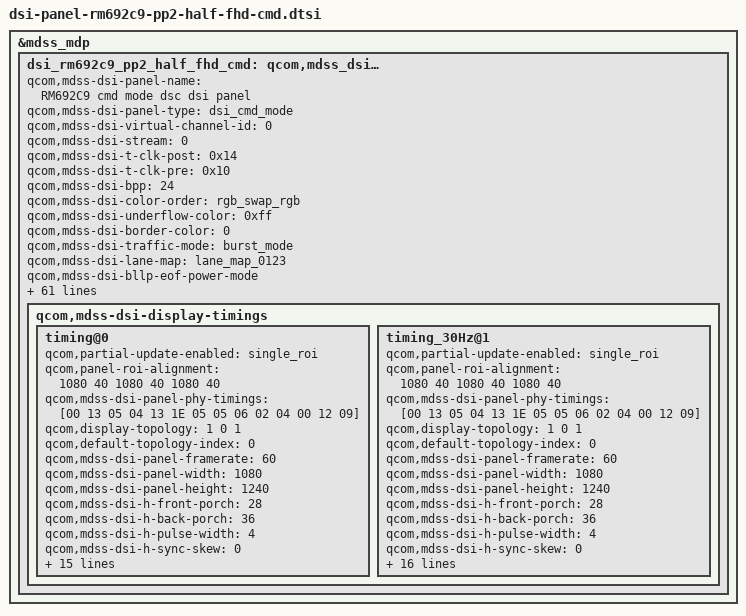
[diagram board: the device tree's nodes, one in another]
/* Copyright (c) 2014, Code Aurora Forum. All rights reserved.
 *
 * This program is free software; you can redistribute it and/or modify
 * it under the terms of the GNU General Public License version 2 and
 * only version 2 as published by the Free Software Foundation.
 *
 * This program is distributed in the hope that it will be useful,
 * but WITHOUT ANY WARRANTY; without even the implied warranty of
 * MERCHANTABILITY or FITNESS FOR A PARTICULAR PURPOSE.  See the
 * GNU General Public License for more details.
 */

&mdss_mdp {
    dsi_rm692c9_pp2_half_fhd_cmd: qcom,mdss_dsi_rm692c9_pp2_half_fhd_cmd {
		qcom,mdss-dsi-panel-name = "RM692C9 cmd mode dsc dsi panel";
		qcom,mdss-dsi-panel-type = "dsi_cmd_mode";
		qcom,mdss-dsi-virtual-channel-id = <0>;
		qcom,mdss-dsi-stream = <0>;
		qcom,mdss-dsi-t-clk-post = <0x14>;
		qcom,mdss-dsi-t-clk-pre = <0x10>;
		qcom,mdss-dsi-bpp = <24>;
		qcom,mdss-dsi-color-order = "rgb_swap_rgb";
		qcom,mdss-dsi-underflow-color = <0xff>;
		qcom,mdss-dsi-border-color = <0>;
		qcom,mdss-dsi-traffic-mode = "burst_mode";
		qcom,mdss-dsi-lane-map = "lane_map_0123";
		qcom,mdss-dsi-bllp-eof-power-mode;
		qcom,mdss-dsi-bllp-power-mode;
		qcom,mdss-dsi-lane-0-state;
		qcom,mdss-dsi-lane-1-state;
		qcom,mdss-dsi-lane-2-state;
		qcom,mdss-dsi-lane-3-state;
		qcom,mdss-dsi-reset-sequence = <1 10>, <0 2>, <1 10>;
		qcom,mdss-dsi-dma-trigger = "trigger_sw";
		qcom,mdss-dsi-mdp-trigger = "none";
		qcom,mdss-dsi-te-pin-select = <1>;
		qcom,panel-te-source = <1>;
		qcom,mdss-dsi-wr-mem-start = <0x2c>;
		qcom,mdss-dsi-wr-mem-continue = <0x3c>;
		qcom,mdss-dsi-te-dcs-command = <1>;
//		qcom,mdss-dsi-te-check-enable;
//		qcom,mdss-dsi-te-using-te-pin;
		qcom,mdss-dsi-lp11-init;
		qcom,mdss-dsi-tx-eot-append;
		qcom,dsi-sec-ctrl-num = <1>;
		qcom,dsi-sec-phy-num = <1>;
		/* qcom,dsi-select-sec-clocks = "src_byte_clk1", "src_pixel_clk1"; */
		qcom,dsi-select-sec-clocks = "mux_byte_clk1", "mux_pixel_clk1";
		qcom,ulps-enabled;
		//qcom,null-insertion-enabled;

		qcom,mdss-dsi-panel-hdr-enabled;
		qcom,mdss-dsi-panel-hdr-color-primaries = <14880 15935 32435 16555 14945 30910 7790 3415>;
		qcom,mdss-dsi-panel-peak-brightness = <5000000>;		/* max. 500nits */
		qcom,mdss-dsi-panel-blackness-level = <6134>;

		qcom,mdss-pan-physical-width-dimension = <69>;
		qcom,mdss-pan-physical-height-dimension = <80>;

		/* Brightness Map List */
		lge,blmap = <
			0
			//0%[10]
			9 9 9 9 9 9 9 9 9 9 10 10 10
			//1%[0] 2%[2] 3%[5] 4%[7] 5%[10] 6%[12] 7%[15] 8%[17] 9%[20] 10%[22]
			10 10 11 11 11 11 11 12 12 12 13 13 14 14 15 16 16 17 17 18 19 21 23 24
			//11%[0] 12%[3] 13%[5] 14%[8] 15%[10] 16%[13] 17%[15] 18%[18] 19%[20] 20%[22]
			26 27 28 29 31 33 34 35 37 39 41 43 45 47 49 51 53 55 57 59 62 65 68 69 71
			//21%[0] 22%[2] 23%[5] 24%[7] 25%[10] 26%[12] 27%[15] 28%[17] 29%[20] 30%[22]
			73 76 80 82 85 88 92 96 98 101 104 107 111 114 117 121 126 131 134 137 140 145 151 156
			//31%[0] 32%[3] 33%[5] 34%[8] 35%[10] 36%[13] 37%[15] 38%[18] 39%[20] 40%[22]
			162 165 169 173 178 184 188 192 197 203 210 214 218 222 228 235 239 243 248 254 260 268 277 282 288
			//41%[0] 42%[2] 43%[5] 44%[7] 45%[10] 46%[12] 47%[15] 48%[17] 49%[20] 50%[22]
			294 302 311 316 321 326 335 345 350 355 361 370 379 384 390 396 405 415 421 427 434 443 452 462
			//51%[0] 52%[3] 53%[5] 54%[8] 55%[10] 56%[13] 57%[15] 58%[18] 59%[20] 60%[22]
			472 478 485 492 503 514 520 527 534 545 556 563 570 578 588 599 606 614 622 634 646 657 669 677 686
			//61%[0] 62%[2] 63%[5] 64%[7] 65%[10] 66%[12] 67%[15] 68%[17] 69%[20] 70%[22]
			695 707 719 727 736 745 756 768 777 786 796 808 821 830 839 848 862 876 886 896 906 919 933 947
			//71%[0] 72%[3] 73%[5] 74%[8] 75%[10] 76%[13] 77%[15] 78%[18] 79%[20] 80%[22]
			961 971 981 991 1006 1021 1031 1041 1051 1065 1080 1091 1102 1114 1129 1144 1155 1167 1179 1198 1218 1233 1248 1259 1271
			//81%[0] 82%[2] 83%[5] 84%[7] 85%[10] 86%[12] 87%[15] 88%[17] 89%[20] 90%[22]
			1283 1300 1317 1330 1343 1356 1376 1396 1410 1424 1438 1457 1477 1490 1503 1517 1538 1560 1574 1588 1602 1622 1642 1661
			//91%[0] 92%[3] 93%[5] 94%[8] 95%[10] 96%[13] 97%[15] 98%[18] 99%[20] 100%[22]
			1681 1693 1705 1718 1738 1759 1772 1786 1800 1821 1843 1856 1870 1884 1904 1925 1940 1955 1971 1992 2014 2070 2126
			2127 2127 2127 2127 2128 2129 2130 2131 2133 2134 2137 2139 2142 2144 2148 2151 2155 2159 2163 2168 2173 2178 2184 2189 2196
			2202 2209 2216 2223 2231 2239 2248 2257 2266 2275 2285 2295 2306 2316 2328 2339 2351 2363 2376 2389 2402 2416 2430 2444 2459
			2474 2489 2505 2521 2538 2555 2572 2590 2608 2626 2645 2664 2684 2704 2724 2745 2766 2788 2810 2832 2855 2878 2901 2925 2949
			2974 2999 3024 3050 3077 3103 3130 3158 3186 3214 3243 3272 3301 3331 3361 3392 3423 3455 3487 3519 3552 3585 3619 3653 3687
			3722 3758 3793 3829 3866 3903 3940 3978 4017 4055
		>;
		lge,blmap-ve = <
			0
			//0%[10]
			9 9 9 9 9 9 9 9 9 9 10 10 10
			//1%[0] 2%[2] 3%[5] 4%[7] 5%[10] 6%[12] 7%[15] 8%[17] 9%[20] 10%[22]
			10 10 11 11 11 11 11 12 12 12 13 13 14 14 15 16 16 17 17 18 19 21 23 24
			//11%[0] 12%[3] 13%[5] 14%[8] 15%[10] 16%[13] 17%[15] 18%[18] 19%[20] 20%[22]
			26 27 28 29 31 33 34 35 37 39 41 43 45 47 49 51 53 55 57 59 62 65 68 69 71
			//21%[0] 22%[2] 23%[5] 24%[7] 25%[10] 26%[12] 27%[15] 28%[17] 29%[20] 30%[22]
			73 76 80 82 85 88 92 96 98 101 104 107 111 114 117 121 126 131 134 137 140 145 151 156
			//31%[0] 32%[3] 33%[5] 34%[8] 35%[10] 36%[13] 37%[15] 38%[18] 39%[20] 40%[22]
			162 165 169 173 178 184 188 192 197 203 210 214 218 222 228 235 239 243 248 254 260 268 277 282 288
			//41%[0] 42%[2] 43%[5] 44%[7] 45%[10] 46%[12] 47%[15] 48%[17] 49%[20] 50%[22]
			294 302 311 316 321 326 335 345 350 355 361 370 379 384 390 396 405 415 421 427 434 443 452 462
			//51%[0] 52%[3] 53%[5] 54%[8] 55%[10] 56%[13] 57%[15] 58%[18] 59%[20] 60%[22]
			472 478 485 492 503 514 520 527 534 545 556 563 570 578 588 599 606 614 622 634 646 657 669 677 686
			//61%[0] 62%[2] 63%[5] 64%[7] 65%[10] 66%[12] 67%[15] 68%[17] 69%[20] 70%[22]
			695 707 719 727 736 745 756 768 777 786 796 808 821 830 839 848 862 876 886 896 906 919 933 947
			//71%[0] 72%[3] 73%[5] 74%[8] 75%[10] 76%[13] 77%[15] 78%[18] 79%[20] 80%[22]
			961 971 981 991 1006 1021 1031 1041 1051 1065 1080 1091 1102 1114 1129 1144 1155 1167 1179 1198 1218 1233 1248 1259 1271
			//81%[0] 82%[2] 83%[5] 84%[7] 85%[10] 86%[12] 87%[15] 88%[17] 89%[20] 90%[22]
			1283 1300 1317 1330 1343 1356 1376 1396 1410 1424 1438 1457 1477 1490 1503 1517 1538 1560 1574 1588 1602 1622 1642 1661
			//91%[0] 92%[3] 93%[5] 94%[8] 95%[10] 96%[13] 97%[15] 98%[18] 99%[20] 100%[22]
			1681 1693 1705 1718 1738 1759 1772 1786 1800 1821 1843 1856 1870 1884 1904 1925 1940 1955 1971 1992 2014 2070 2126
			2127 2127 2127 2127 2128 2129 2130 2131 2133 2134 2137 2139 2142 2144 2148 2151 2155 2159 2163 2168 2173 2178 2184 2189 2196
			2202 2209 2216 2223 2231 2239 2248 2257 2266 2275 2285 2295 2306 2316 2328 2339 2351 2363 2376 2389 2402 2416 2430 2444 2459
			2474 2489 2505 2521 2538 2555 2572 2590 2608 2626 2645 2664 2684 2704 2724 2745 2766 2788 2810 2832 2855 2878 2901 2925 2949
			2974 2999 3024 3050 3077 3103 3130 3158 3186 3214 3243 3272 3301 3331 3361 3392 3423 3455 3487 3519 3552 3585 3619 3653 3687
			3722 3758 3793 3829 3866 3903 3940 3978 4017 4055
		>;
		lge,blmap-hdr = <
			0
			//0%[10]
			9 9 9 9 9 9 9 9 9 9 10 10 10
			//1%[0] 2%[2] 3%[5] 4%[7] 5%[10] 6%[12] 7%[15] 8%[17] 9%[20] 10%[22]
			10 10 11 11 11 11 11 12 12 12 13 13 14 14 15 16 16 17 17 18 19 21 23 24
			//11%[0] 12%[3] 13%[5] 14%[8] 15%[10] 16%[13] 17%[15] 18%[18] 19%[20] 20%[22]
			26 27 28 29 31 33 34 35 37 39 41 43 45 47 49 51 53 55 57 59 62 65 68 69 71
			//21%[0] 22%[2] 23%[5] 24%[7] 25%[10] 26%[12] 27%[15] 28%[17] 29%[20] 30%[22]
			73 76 80 82 85 88 92 96 98 101 104 107 111 114 117 121 126 131 134 137 140 145 151 156
			//31%[0] 32%[3] 33%[5] 34%[8] 35%[10] 36%[13] 37%[15] 38%[18] 39%[20] 40%[22]
			162 165 169 173 178 184 188 192 197 203 210 214 218 222 228 235 239 243 248 254 260 268 277 282 288
			//41%[0] 42%[2] 43%[5] 44%[7] 45%[10] 46%[12] 47%[15] 48%[17] 49%[20] 50%[22]
			294 302 311 316 321 326 335 345 350 355 361 370 379 384 390 396 405 415 421 427 434 443 452 462
			//51%[0] 52%[3] 53%[5] 54%[8] 55%[10] 56%[13] 57%[15] 58%[18] 59%[20] 60%[22]
			472 478 485 492 503 514 520 527 534 545 556 563 570 578 588 599 606 614 622 634 646 657 669 677 686
			//61%[0] 62%[2] 63%[5] 64%[7] 65%[10] 66%[12] 67%[15] 68%[17] 69%[20] 70%[22]
			695 707 719 727 736 745 756 768 777 786 796 808 821 830 839 848 862 876 886 896 906 919 933 947
			//71%[0] 72%[3] 73%[5] 74%[8] 75%[10] 76%[13] 77%[15] 78%[18] 79%[20] 80%[22]
			961 971 981 991 1006 1021 1031 1041 1051 1065 1080 1091 1102 1114 1129 1144 1155 1167 1179 1198 1218 1233 1248 1259 1271
			//81%[0] 82%[2] 83%[5] 84%[7] 85%[10] 86%[12] 87%[15] 88%[17] 89%[20] 90%[22]
			1283 1300 1317 1330 1343 1356 1376 1396 1410 1424 1438 1457 1477 1490 1503 1517 1538 1560 1574 1588 1602 1622 1642 1661
			//91%[0] 92%[3] 93%[5] 94%[8] 95%[10] 96%[13] 97%[15] 98%[18] 99%[20] 100%[22]
			1681 1693 1705 1718 1738 1759 1772 1786 1800 1821 1843 1856 1870 1884 1904 1925 1940 1955 1971 1992 2014 2070 2126
			2127 2127 2127 2127 2128 2129 2130 2131 2133 2134 2137 2139 2142 2144 2148 2151 2155 2159 2163 2168 2173 2178 2184 2189 2196
			2202 2209 2216 2223 2231 2239 2248 2257 2266 2275 2285 2295 2306 2316 2328 2339 2351 2363 2376 2389 2402 2416 2430 2444 2459
			2474 2489 2505 2521 2538 2555 2572 2590 2608 2626 2645 2664 2684 2704 2724 2745 2766 2788 2810 2832 2855 2878 2901 2925 2949
			2974 2999 3024 3050 3077 3103 3130 3158 3186 3214 3243 3272 3301 3331 3361 3392 3423 3455 3487 3519 3552 3585 3619 3653 3687
			3722 3758 3793 3829 3866 3903 3940 3978 4017 4055
		>;

		lge,use-color-manager;
		lge,use-color-manager-oled;

		lge,mdss-dsi-disp-ctrl-command-1 = [
			15 01 00 00 00 00 02 FE 00
			15 01 00 00 00 00 02 5C 00
			15 01 00 00 00 00 02 FE 80
			15 01 00 00 00 00 02 00 4F
			15 01 00 00 00 00 02 05 00
			15 00 00 00 00 00 02 FE 12
			15 00 00 00 00 00 02 84 00
			15 01 00 00 00 00 02 FE 00
		];
		lge,mdss-dsi-disp-ctrl-command-1-state = "dsi_lp_mode";

		lge,color-mode-cmds-dummy = [
			15 00 00 00 00 00 02 FE 00
			15 00 00 00 00 00 02 5A 0B
			15 00 00 00 00 00 02 5C 00
			15 00 00 00 00 00 02 FE 80
			15 00 00 00 00 00 02 00 4F
			15 00 00 00 00 00 02 08 DF
			15 00 00 00 00 00 02 09 EE
			15 00 00 00 00 00 02 0A ED
			15 00 00 00 00 00 02 0B FC
			15 00 00 00 00 00 02 0C F0
			15 00 00 00 00 00 02 0D FB
			15 00 00 00 00 00 02 0E 00
			15 00 00 00 00 00 02 0F 01
			15 00 00 00 00 00 02 14 3F
			15 00 00 00 00 00 02 15 B3
			15 00 00 00 00 00 02 16 74
			15 00 00 00 00 00 02 17 FF
			15 00 00 00 00 00 02 18 AD
			15 00 00 00 00 00 02 19 3F
			15 00 00 00 00 00 02 1A C9
			15 00 00 00 00 00 02 1B 07
			15 00 00 00 00 00 02 FE 10
			15 00 00 00 00 00 02 00 9C
			15 00 00 00 00 00 02 01 57
			15 00 00 00 00 00 02 02 05
			15 00 00 00 00 00 02 03 14
			15 00 00 00 00 00 02 04 10
			15 00 00 00 00 00 02 05 01
			15 00 00 00 00 00 02 06 6C
			15 00 00 00 00 00 02 07 A7
			15 00 00 00 00 00 02 08 02
			15 00 00 00 00 00 02 09 06
			15 00 00 00 00 00 02 0A 00
			15 00 00 00 00 00 02 0B 00
			15 00 00 00 00 00 02 0C 8D
			15 00 00 00 00 00 02 0D 07
			15 00 00 00 00 00 02 FE 12
			15 00 00 00 00 00 02 84 00
			15 00 00 00 00 00 02 83 10
			15 01 00 00 00 00 02 FE 00
		];
		lge,color-mode-cmds-dummy-state = "dsi_lp_mode";

		lge,use-color-manager-lut;
		lge,cm-lut-screen-mode-set-name = "nat", "viv", "cin";
		lge,cm-lut-screen-mode-set-cnt = <40>;
		lge,cm-lut-screen-mode-set = [
			00 0B 00 80 4F DF EE ED FC F0 FB 00 01 3F B3 74 FF AD 3F C9 07 10 9C 57 05 14 10 01 6C A7 02 06 00 00 8D 07 12 00 10 00
			00 0B 00 80 4F 80 33 0E 23 32 62 EF 0F 14 2C 5F F7 FF 06 97 0B 10 3C 57 05 14 10 01 5C A7 02 06 00 00 EF 07 12 00 10 00
			00 0B 00 80 4F 00 00 EF FF DE EE 0F 00 3F EF 14 FF CD 35 CD 03 10 AF 57 05 14 10 01 A0 A7 02 06 00 00 10 07 12 00 10 00
		];

		lge,cm-lut-hue-cnt = <8>;
		lge,cm-lut-hue = [
			D8 49 B9 71 39 93 00 00
			84 06 97 40 F3 61 00 02
			3F B3 74 FF AD 3F C9 07
			FB 71 51 BE 57 FC CB 0F
			C6 2E 3D 7D 11 C9 DF 0F
		];

		lge,cm-lut-saturation-cnt = <13>;
		lge,cm-lut-saturation = [
			00 0B 00 80 4F 99 AA A9 98 9A 95 00 00
			00 0B 00 80 4F BC CC CB CA CD C8 00 00
			00 0B 00 80 4F DF EE ED FC F0 FB 00 01
			00 0B 00 80 4F F2 00 0F 2E 23 2E AD 0B
			00 0B 00 80 4F 15 22 21 50 56 51 FF 0F
		];

		lge,cm-lut-sharpness-cnt = <1>;
		lge,cm-lut-sharpness = [08 12 1C 26 30];

		lge,cm-lut-rgb-cnt = <14>;
		lge,cm-lut-rgb = [
			1C 57 05 14 10 01 C0 A7 02 06 00 00 23 07
			7C 57 05 14 10 01 C0 A7 02 06 00 00 77 07
			9C 57 05 14 10 01 6C A7 02 06 00 00 8D 07
			9C 57 05 14 10 01 2C A7 02 06 00 00 92 07
			9C 57 05 14 10 01 DC A6 02 06 00 00 98 07
		];

		/* Video Enahnacement */
		lge,mdss-dsi-ve-on-command = [
			15 00 00 00 00 00 02 FE 80
			15 00 00 00 00 00 02 00 4F
			15 00 00 00 00 00 02 08 F2
			15 00 00 00 00 00 02 09 00
			15 00 00 00 00 00 02 0A 0F
			15 00 00 00 00 00 02 0B 2E
			15 00 00 00 00 00 02 0C 23
			15 00 00 00 00 00 02 0D 2E
			15 00 00 00 00 00 02 0E AD
			15 00 00 00 00 00 02 0F 0B
			15 01 00 00 00 00 02 FE 00
		];
		lge,mdss-dsi-ve-on-command-state = "dsi_lp_mode";

		qcom,mdss-dsi-display-timings {
			timing@0{
				qcom,partial-update-enabled = "single_roi";
				qcom,panel-roi-alignment = <1080 40 1080 40 1080 40>;
				qcom,mdss-dsi-panel-phy-timings = [00 13 05 04 13 1E 05 05 06 02 04 00 12 09];
				//qcom,mdss-dsi-panel-clockrate = <435355200>;
				qcom,display-topology = <1 0 1>;
				qcom,default-topology-index = <0>;
				qcom,mdss-dsi-panel-framerate = <60>;
				qcom,mdss-dsi-panel-width = <1080>;
				qcom,mdss-dsi-panel-height = <1240>;
				qcom,mdss-dsi-h-front-porch = <28>;
				qcom,mdss-dsi-h-back-porch = <36>;
				qcom,mdss-dsi-h-pulse-width = <4>;
				qcom,mdss-dsi-h-sync-skew = <0>;
				qcom,mdss-dsi-v-back-porch = <8>;
				qcom,mdss-dsi-v-front-porch = <16>;
				qcom,mdss-dsi-v-pulse-width = <4>;
				qcom,mdss-dsi-h-left-border = <0>;
				qcom,mdss-dsi-h-right-border = <0>;
				qcom,mdss-dsi-v-top-border = <0>;
				qcom,mdss-dsi-v-bottom-border = <0>;
				qcom,mdss-dsi-h-sync-pulse = <0>;
				//qcom,mdss-mdp-transfer-time-us = <15000>;

				qcom,mdss-dsi-on-command = [
					15 00 00 00 00 00 02 FE 00
					15 00 00 00 00 00 02 5A 0B
					15 00 00 00 00 00 02 5C 00
					15 01 00 00 00 00 02 FE 00
					15 00 00 00 00 00 02 FE 80
					15 00 00 00 00 00 02 00 4F
					15 00 00 00 00 00 02 08 DF
					15 00 00 00 00 00 02 09 EE
					15 00 00 00 00 00 02 0A ED
					15 00 00 00 00 00 02 0B FC
					15 00 00 00 00 00 02 0C F0
					15 00 00 00 00 00 02 0D FB
					15 00 00 00 00 00 02 0E 00
					15 00 00 00 00 00 02 0F 01
					15 00 00 00 00 00 02 14 3F
					15 00 00 00 00 00 02 15 B3
					15 00 00 00 00 00 02 16 74
					15 00 00 00 00 00 02 17 FF
					15 00 00 00 00 00 02 18 AD
					15 00 00 00 00 00 02 19 3F
					15 00 00 00 00 00 02 1A C9
					15 00 00 00 00 00 02 1B 07
					15 01 00 00 00 00 02 FE 00
					15 00 00 00 00 00 02 FE 10
					15 00 00 00 00 00 02 00 9C
					15 00 00 00 00 00 02 01 57
					15 00 00 00 00 00 02 02 05
					15 00 00 00 00 00 02 03 14
					15 00 00 00 00 00 02 04 10
					15 00 00 00 00 00 02 05 01
					15 00 00 00 00 00 02 06 6C
					15 00 00 00 00 00 02 07 A7
					15 00 00 00 00 00 02 08 02
					15 00 00 00 00 00 02 09 06
					15 00 00 00 00 00 02 0A 00
					15 00 00 00 00 00 02 0B 00
					15 00 00 00 00 00 02 0C 8D
					15 00 00 00 00 00 02 0D 07
					15 01 00 00 00 00 02 FE 00
					15 00 00 00 00 00 02 FE 10
					15 00 00 00 00 00 02 0E 00
					15 00 00 00 00 00 02 0F 00
					15 00 00 00 00 00 02 10 00
					15 00 00 00 00 00 02 11 01
					15 00 00 00 00 00 02 12 00
					15 00 00 00 00 00 02 13 07
					15 00 00 00 00 00 02 14 12
					15 00 00 00 00 00 02 15 00
					15 00 00 00 00 00 02 16 19
					15 00 00 00 00 00 02 17 23
					15 00 00 00 00 00 02 18 00
					15 00 00 00 00 00 02 19 2D
					15 00 00 00 00 00 02 1A 33
					15 00 00 00 00 00 02 1B 00
					15 00 00 00 00 00 02 1C 3A
					15 00 00 00 00 00 02 1D 58
					15 00 00 00 00 00 02 1E 00
					15 00 00 00 00 00 02 1F 7D
					15 00 00 00 00 00 02 20 93
					15 00 00 00 00 00 02 21 00
					15 00 00 00 00 00 02 22 AA
					15 00 00 00 00 00 02 23 DF
					15 00 00 00 00 00 02 24 10
					15 00 00 00 00 00 02 25 1D
					15 00 00 00 00 00 02 26 62
					15 00 00 00 00 00 02 27 11
					15 00 00 00 00 00 02 28 B1
					15 00 00 00 00 00 02 29 08
					15 00 00 00 00 00 02 2A 22
					15 00 00 00 00 00 02 2B 69
					15 00 00 00 00 00 02 2D D3
					15 00 00 00 00 00 02 2F 32
					15 00 00 00 00 00 02 30 47
					15 00 00 00 00 00 02 31 C5
					15 00 00 00 00 00 02 32 43
					15 00 00 00 00 00 02 33 4C
					15 00 00 00 00 00 02 34 DE
					15 00 00 00 00 00 02 35 54
					15 00 00 00 00 00 02 36 7A
					15 00 00 00 00 00 02 37 20
					15 00 00 00 00 00 02 38 66
					15 00 00 00 00 00 02 39 D1
					15 00 00 00 00 00 02 3A 8D
					15 00 00 00 00 00 02 3B 87
					15 00 00 00 00 00 02 3D 54
					15 00 00 00 00 00 02 3F 26
					15 00 00 00 00 00 02 40 A9
					15 00 00 00 00 00 02 41 03
					15 00 00 00 00 00 02 42 EB
					15 00 00 00 00 00 02 43 BA
					15 00 00 00 00 00 02 44 DF
					15 00 00 00 00 00 02 45 DF
					15 00 00 00 00 00 02 46 DC
					15 00 00 00 00 00 02 47 EA
					15 00 00 00 00 00 02 48 01
					15 00 00 00 00 00 02 49 FF
					15 00 00 00 00 00 02 4A 91
					15 00 00 00 00 00 02 4B DA
					15 00 00 00 00 00 02 4C FF
					15 00 00 00 00 00 02 4D FF
					15 00 00 00 00 00 02 4E 00
					15 00 00 00 00 00 02 4F 00
					15 00 00 00 00 00 02 50 00
					15 00 00 00 00 00 02 51 02
					15 00 00 00 00 00 02 52 00
					15 00 00 00 00 00 02 53 08
					15 00 00 00 00 00 02 54 13
					15 00 00 00 00 00 02 55 00
					15 00 00 00 00 00 02 56 1B
					15 00 00 00 00 00 02 58 25
					15 00 00 00 00 00 02 59 00
					15 00 00 00 00 00 02 5A 30
					15 00 00 00 00 00 02 5B 36
					15 00 00 00 00 00 02 5C 00
					15 00 00 00 00 00 02 5D 3D
					15 00 00 00 00 00 02 5E 5C
					15 00 00 00 00 00 02 5F 00
					15 00 00 00 00 00 02 60 83
					15 00 00 00 00 00 02 61 99
					15 00 00 00 00 00 02 62 00
					15 00 00 00 00 00 02 63 B2
					15 00 00 00 00 00 02 64 E8
					15 00 00 00 00 00 02 65 10
					15 00 00 00 00 00 02 66 27
					15 00 00 00 00 00 02 67 6E
					15 00 00 00 00 00 02 68 11
					15 00 00 00 00 00 02 69 BE
					15 00 00 00 00 00 02 6A 17
					15 00 00 00 00 00 02 6B 22
					15 00 00 00 00 00 02 6C 79
					15 00 00 00 00 00 02 6D E4
					15 00 00 00 00 00 02 6E 32
					15 00 00 00 00 00 02 6F 59
					15 00 00 00 00 00 02 70 D7
					15 00 00 00 00 00 02 71 43
					15 00 00 00 00 00 02 72 5F
					15 00 00 00 00 00 02 73 F1
					15 00 00 00 00 00 02 74 54
					15 00 00 00 00 00 02 75 8E
					15 00 00 00 00 00 02 76 34
					15 00 00 00 00 00 02 77 66
					15 00 00 00 00 00 02 78 E5
					15 00 00 00 00 00 02 79 A0
					15 00 00 00 00 00 02 7A 87
					15 00 00 00 00 00 02 7B 66
					15 00 00 00 00 00 02 7C 37
					15 00 00 00 00 00 02 7D A9
					15 00 00 00 00 00 02 7E 13
					15 00 00 00 00 00 02 7F F9
					15 00 00 00 00 00 02 80 BA
					15 00 00 00 00 00 02 81 EB
					15 00 00 00 00 00 02 82 E8
					15 00 00 00 00 00 02 83 DC
					15 00 00 00 00 00 02 84 F1
					15 00 00 00 00 00 02 85 04
					15 00 00 00 00 00 02 86 FF
					15 00 00 00 00 00 02 87 92
					15 00 00 00 00 00 02 88 DB
					15 00 00 00 00 00 02 89 FF
					15 00 00 00 00 00 02 8A FF
					15 00 00 00 00 00 02 8B 00
					15 00 00 00 00 00 02 8C 00
					15 00 00 00 00 00 02 8D 00
					15 00 00 00 00 00 02 8E 02
					15 00 00 00 00 00 02 8F 00
					15 00 00 00 00 00 02 90 08
					15 00 00 00 00 00 02 91 15
					15 00 00 00 00 00 02 92 00
					15 00 00 00 00 00 02 93 1D
					15 00 00 00 00 00 02 94 27
					15 00 00 00 00 00 02 95 00
					15 00 00 00 00 00 02 96 33
					15 00 00 00 00 00 02 97 3A
					15 00 00 00 00 00 02 98 00
					15 00 00 00 00 00 02 99 41
					15 00 00 00 00 00 02 9A 61
					15 00 00 00 00 00 02 9B 00
					15 00 00 00 00 00 02 9C 89
					15 00 00 00 00 00 02 9D A0
					15 00 00 00 00 00 02 9E 00
					15 00 00 00 00 00 02 9F B9
					15 00 00 00 00 00 02 A0 F1
					15 00 00 00 00 00 02 A2 10
					15 00 00 00 00 00 02 A3 31
					15 00 00 00 00 00 02 A4 7A
					15 00 00 00 00 00 02 A5 11
					15 00 00 00 00 00 02 A6 CB
					15 00 00 00 00 00 02 A7 25
					15 00 00 00 00 00 02 A9 22
					15 00 00 00 00 00 02 AA 88
					15 00 00 00 00 00 02 AB F5
					15 00 00 00 00 00 02 AC 32
					15 00 00 00 00 00 02 AD 6B
					15 00 00 00 00 00 02 AE EA
					15 00 00 00 00 00 02 AF 43
					15 00 00 00 00 00 02 B0 73
					15 00 00 00 00 00 02 B1 05
					15 00 00 00 00 00 02 B2 55
					15 00 00 00 00 00 02 B3 A2
					15 00 00 00 00 00 02 B4 48
					15 00 00 00 00 00 02 B5 66
					15 00 00 00 00 00 02 B6 F9
					15 00 00 00 00 00 02 B7 B4
					15 00 00 00 00 00 02 B8 87
					15 00 00 00 00 00 02 B9 79
					15 00 00 00 00 00 02 BA 48
					15 00 00 00 00 00 02 BB A9
					15 00 00 00 00 00 02 BC 23
					15 00 00 00 00 00 02 BD 07
					15 00 00 00 00 00 02 BE BB
					15 00 00 00 00 00 02 BF F7
					15 00 00 00 00 00 02 C0 F2
					15 00 00 00 00 00 02 C1 DC
					15 00 00 00 00 00 02 C2 F7
					15 00 00 00 00 00 02 C3 07
					15 00 00 00 00 00 02 C4 FF
					15 00 00 00 00 00 02 C5 94
					15 00 00 00 00 00 02 C6 DB
					15 00 00 00 00 00 02 C7 FF
					15 00 00 00 00 00 02 C8 FF
					15 01 00 00 00 00 02 FE 00
					15 00 00 00 00 00 02 FE 12
					15 00 00 00 00 00 02 00 00
					15 00 00 00 00 00 02 01 30
					15 00 00 00 00 00 02 02 00
					15 00 00 00 00 00 02 03 48
					15 00 00 00 00 00 02 04 60
					15 00 00 00 00 00 02 05 00
					15 00 00 00 00 00 02 06 88
					15 00 00 00 00 00 02 07 B8
					15 00 00 00 00 00 02 08 00
					15 00 00 00 00 00 02 09 F8
					15 00 00 00 00 00 02 0A 4E
					15 00 00 00 00 00 02 0B 10
					15 00 00 00 00 00 02 0C C4
					15 00 00 00 00 00 02 0D 1B
					15 00 00 00 00 00 02 0E 21
					15 00 00 00 00 00 02 0F 63
					15 00 00 00 00 00 02 10 D9
					15 00 00 00 00 00 02 11 22
					15 00 00 00 00 00 02 12 3A
					15 00 00 00 00 00 02 13 8E
					15 00 00 00 00 00 02 14 33
					15 00 00 00 00 00 02 15 D9
					15 00 00 00 00 00 02 16 5D
					15 00 00 00 00 00 02 17 43
					15 00 00 00 00 00 02 18 CE
					15 00 00 00 00 00 02 19 34
					15 00 00 00 00 00 02 1A 54
					15 00 00 00 00 00 02 1B 90
					15 00 00 00 00 00 02 1C E5
					15 00 00 00 00 00 02 1D 55
					15 00 00 00 00 00 02 1E 35
					15 00 00 00 00 00 02 1F 7F
					15 00 00 00 00 00 02 20 66
					15 00 00 00 00 00 02 21 C6
					15 00 00 00 00 00 02 22 08
					15 00 00 00 00 00 02 23 76
					15 00 00 00 00 00 02 24 48
					15 00 00 00 00 00 02 25 85
					15 00 00 00 00 00 02 26 77
					15 00 00 00 00 00 02 27 C0
					15 00 00 00 00 00 02 28 F8
					15 00 00 00 00 00 02 29 77
					15 00 00 00 00 00 02 2A 00
					15 00 00 00 00 00 02 2B 28
					15 00 00 00 00 00 02 2D 00
					15 00 00 00 00 00 02 2F 40
					15 00 00 00 00 00 02 30 60
					15 00 00 00 00 00 02 31 00
					15 00 00 00 00 00 02 32 80
					15 00 00 00 00 00 02 33 B0
					15 00 00 00 00 00 02 34 00
					15 00 00 00 00 00 02 35 F0
					15 00 00 00 00 00 02 36 46
					15 00 00 00 00 00 02 37 10
					15 00 00 00 00 00 02 38 BB
					15 00 00 00 00 00 02 39 12
					15 00 00 00 00 00 02 3A 21
					15 00 00 00 00 00 02 3B 59
					15 00 00 00 00 00 02 3D CF
					15 00 00 00 00 00 02 3F 22
					15 00 00 00 00 00 02 40 30
					15 00 00 00 00 00 02 41 84
					15 00 00 00 00 00 02 42 33
					15 00 00 00 00 00 02 43 D0
					15 00 00 00 00 00 02 44 54
					15 00 00 00 00 00 02 45 43
					15 00 00 00 00 00 02 46 C6
					15 00 00 00 00 00 02 47 2D
					15 00 00 00 00 00 02 48 54
					15 00 00 00 00 00 02 49 89
					15 00 00 00 00 00 02 4A DF
					15 00 00 00 00 00 02 4B 55
					15 00 00 00 00 00 02 4C 2F
					15 00 00 00 00 00 02 4D 7B
					15 00 00 00 00 00 02 4E 66
					15 00 00 00 00 00 02 4F C2
					15 00 00 00 00 00 02 50 05
					15 00 00 00 00 00 02 51 76
					15 00 00 00 00 00 02 52 46
					15 00 00 00 00 00 02 53 84
					15 00 00 00 00 00 02 54 77
					15 00 00 00 00 00 02 55 BF
					15 00 00 00 00 00 02 56 F8
					15 00 00 00 00 00 02 58 77
					15 00 00 00 00 00 02 59 00
					15 00 00 00 00 00 02 5A 28
					15 00 00 00 00 00 02 5B 00
					15 00 00 00 00 00 02 5C 40
					15 00 00 00 00 00 02 5D 58
					15 00 00 00 00 00 02 5E 00
					15 00 00 00 00 00 02 5F 80
					15 00 00 00 00 00 02 60 AC
					15 00 00 00 00 00 02 61 00
					15 00 00 00 00 00 02 62 EB
					15 00 00 00 00 00 02 63 3E
					15 00 00 00 00 00 02 64 10
					15 00 00 00 00 00 02 65 B2
					15 00 00 00 00 00 02 66 08
					15 00 00 00 00 00 02 67 21
					15 00 00 00 00 00 02 68 50
					15 00 00 00 00 00 02 69 C5
					15 00 00 00 00 00 02 6A 22
					15 00 00 00 00 00 02 6B 27
					15 00 00 00 00 00 02 6C 7B
					15 00 00 00 00 00 02 6D 33
					15 00 00 00 00 00 02 6E C6
					15 00 00 00 00 00 02 6F 4B
					15 00 00 00 00 00 02 70 43
					15 00 00 00 00 00 02 71 BE
					15 00 00 00 00 00 02 72 25
					15 00 00 00 00 00 02 73 54
					15 00 00 00 00 00 02 74 83
					15 00 00 00 00 00 02 75 D9
					15 00 00 00 00 00 02 76 55
					15 00 00 00 00 00 02 77 2A
					15 00 00 00 00 00 02 78 76
					15 00 00 00 00 00 02 79 66
					15 00 00 00 00 00 02 7A BE
					15 00 00 00 00 00 02 7B 02
					15 00 00 00 00 00 02 7C 76
					15 00 00 00 00 00 02 7D 44
					15 00 00 00 00 00 02 7E 82
					15 00 00 00 00 00 02 7F 77
					15 00 00 00 00 00 02 80 BE
					15 00 00 00 00 00 02 81 F8
					15 00 00 00 00 00 02 82 77
					15 01 00 00 00 00 02 FE 00
					15 00 00 00 00 00 02 FE 12
					15 00 00 00 00 00 02 84 00
					15 01 00 00 00 00 02 FE 00
					15 00 00 00 00 00 02 FE 12
					15 00 00 00 00 00 02 86 00
					15 00 00 00 00 00 02 87 00
					15 00 00 00 00 00 02 88 00
					15 00 00 00 00 00 02 83 10
					15 01 00 00 00 00 02 FE 00
					15 00 00 00 00 00 02 FE 40
					15 00 00 00 00 00 02 0D 18
					15 01 00 00 00 00 02 FE 00
					15 00 00 00 00 00 02 C2 08
					15 01 00 00 00 00 02 35 00
					05 01 00 00 78 00 01 11
					05 01 00 00 28 00 01 29
				];

				qcom,mdss-dsi-off-command = [
					05 01 00 00 20 00 01 28
					05 01 00 00 10 00 01 10
				];

				qcom,mdss-dsi-on-command-state = "dsi_lp_mode";
				qcom,mdss-dsi-off-command-state = "dsi_lp_mode";

				qcom,mode-control-dsi-state = "dsi_lp_mode";
			};

			timing_30Hz@1{
				qcom,partial-update-enabled = "single_roi";
				qcom,panel-roi-alignment = <1080 40 1080 40 1080 40>;
				qcom,mdss-dsi-panel-phy-timings = [00 13 05 04 13 1E 05 05 06 02 04 00 12 09];
				//qcom,mdss-dsi-panel-clockrate = <435355200>;
				qcom,display-topology = <1 0 1>;
				qcom,default-topology-index = <0>;
				qcom,mdss-dsi-panel-framerate = <60>;
				qcom,mdss-dsi-panel-width = <1080>;
				qcom,mdss-dsi-panel-height = <1240>;
				qcom,mdss-dsi-h-front-porch = <28>;
				qcom,mdss-dsi-h-back-porch = <36>;
				qcom,mdss-dsi-h-pulse-width = <4>;
				qcom,mdss-dsi-h-sync-skew = <0>;
				qcom,mdss-dsi-v-back-porch = <8>;
				qcom,mdss-dsi-v-front-porch = <16>;
				qcom,mdss-dsi-v-pulse-width = <4>;
				qcom,mdss-dsi-h-left-border = <0>;
				qcom,mdss-dsi-h-right-border = <0>;
				qcom,mdss-dsi-v-top-border = <0>;
				qcom,mdss-dsi-v-bottom-border = <0>;
				qcom,mdss-dsi-h-sync-pulse = <0>;
				//qcom,mdss-mdp-transfer-time-us = <15000>;
				lge,mdss-dsi-panel-framerate-div = <2>;

				qcom,mdss-dsi-on-command = [
					15 00 00 00 00 00 02 FE 00
					15 00 00 00 00 00 02 5A 0B
					15 00 00 00 00 00 02 5C 00
					15 01 00 00 00 00 02 FE 00
					15 00 00 00 00 00 02 FE 80
					15 00 00 00 00 00 02 00 4F
					15 00 00 00 00 00 02 08 DF
					15 00 00 00 00 00 02 09 EE
					15 00 00 00 00 00 02 0A ED
					15 00 00 00 00 00 02 0B FC
					15 00 00 00 00 00 02 0C F0
					15 00 00 00 00 00 02 0D FB
					15 00 00 00 00 00 02 0E 00
					15 00 00 00 00 00 02 0F 01
					15 00 00 00 00 00 02 14 3F
					15 00 00 00 00 00 02 15 B3
					15 00 00 00 00 00 02 16 74
					15 00 00 00 00 00 02 17 FF
					15 00 00 00 00 00 02 18 AD
					15 00 00 00 00 00 02 19 3F
					15 00 00 00 00 00 02 1A C9
					15 00 00 00 00 00 02 1B 07
					15 01 00 00 00 00 02 FE 00
					15 00 00 00 00 00 02 FE 10
					15 00 00 00 00 00 02 00 9C
					15 00 00 00 00 00 02 01 57
					15 00 00 00 00 00 02 02 05
					15 00 00 00 00 00 02 03 14
					15 00 00 00 00 00 02 04 10
					15 00 00 00 00 00 02 05 01
					15 00 00 00 00 00 02 06 6C
					15 00 00 00 00 00 02 07 A7
					15 00 00 00 00 00 02 08 02
					15 00 00 00 00 00 02 09 06
					15 00 00 00 00 00 02 0A 00
					15 00 00 00 00 00 02 0B 00
					15 00 00 00 00 00 02 0C 8D
					15 00 00 00 00 00 02 0D 07
					15 01 00 00 00 00 02 FE 00
					15 00 00 00 00 00 02 FE 10
					15 00 00 00 00 00 02 0E 00
					15 00 00 00 00 00 02 0F 00
					15 00 00 00 00 00 02 10 00
					15 00 00 00 00 00 02 11 01
					15 00 00 00 00 00 02 12 00
					15 00 00 00 00 00 02 13 07
					15 00 00 00 00 00 02 14 12
					15 00 00 00 00 00 02 15 00
					15 00 00 00 00 00 02 16 19
					15 00 00 00 00 00 02 17 23
					15 00 00 00 00 00 02 18 00
					15 00 00 00 00 00 02 19 2D
					15 00 00 00 00 00 02 1A 33
					15 00 00 00 00 00 02 1B 00
					15 00 00 00 00 00 02 1C 3A
					15 00 00 00 00 00 02 1D 58
					15 00 00 00 00 00 02 1E 00
					15 00 00 00 00 00 02 1F 7D
					15 00 00 00 00 00 02 20 93
					15 00 00 00 00 00 02 21 00
					15 00 00 00 00 00 02 22 AA
					15 00 00 00 00 00 02 23 DF
					15 00 00 00 00 00 02 24 10
					15 00 00 00 00 00 02 25 1D
					15 00 00 00 00 00 02 26 62
					15 00 00 00 00 00 02 27 11
					15 00 00 00 00 00 02 28 B1
					15 00 00 00 00 00 02 29 08
					15 00 00 00 00 00 02 2A 22
					15 00 00 00 00 00 02 2B 69
					15 00 00 00 00 00 02 2D D3
					15 00 00 00 00 00 02 2F 32
					15 00 00 00 00 00 02 30 47
					15 00 00 00 00 00 02 31 C5
					15 00 00 00 00 00 02 32 43
					15 00 00 00 00 00 02 33 4C
					15 00 00 00 00 00 02 34 DE
					15 00 00 00 00 00 02 35 54
					15 00 00 00 00 00 02 36 7A
					15 00 00 00 00 00 02 37 20
					15 00 00 00 00 00 02 38 66
					15 00 00 00 00 00 02 39 D1
					15 00 00 00 00 00 02 3A 8D
					15 00 00 00 00 00 02 3B 87
					15 00 00 00 00 00 02 3D 54
					15 00 00 00 00 00 02 3F 26
					15 00 00 00 00 00 02 40 A9
					15 00 00 00 00 00 02 41 03
					15 00 00 00 00 00 02 42 EB
					15 00 00 00 00 00 02 43 BA
					15 00 00 00 00 00 02 44 DF
					15 00 00 00 00 00 02 45 DF
					15 00 00 00 00 00 02 46 DC
					15 00 00 00 00 00 02 47 EA
					15 00 00 00 00 00 02 48 01
					15 00 00 00 00 00 02 49 FF
					15 00 00 00 00 00 02 4A 91
					15 00 00 00 00 00 02 4B DA
					15 00 00 00 00 00 02 4C FF
					15 00 00 00 00 00 02 4D FF
					15 00 00 00 00 00 02 4E 00
					15 00 00 00 00 00 02 4F 00
					15 00 00 00 00 00 02 50 00
					15 00 00 00 00 00 02 51 02
					15 00 00 00 00 00 02 52 00
					15 00 00 00 00 00 02 53 08
					15 00 00 00 00 00 02 54 13
					15 00 00 00 00 00 02 55 00
					15 00 00 00 00 00 02 56 1B
					15 00 00 00 00 00 02 58 25
					15 00 00 00 00 00 02 59 00
					15 00 00 00 00 00 02 5A 30
					15 00 00 00 00 00 02 5B 36
					15 00 00 00 00 00 02 5C 00
					15 00 00 00 00 00 02 5D 3D
					15 00 00 00 00 00 02 5E 5C
					15 00 00 00 00 00 02 5F 00
					15 00 00 00 00 00 02 60 83
					15 00 00 00 00 00 02 61 99
					15 00 00 00 00 00 02 62 00
					15 00 00 00 00 00 02 63 B2
					15 00 00 00 00 00 02 64 E8
					15 00 00 00 00 00 02 65 10
					15 00 00 00 00 00 02 66 27
					15 00 00 00 00 00 02 67 6E
					15 00 00 00 00 00 02 68 11
					15 00 00 00 00 00 02 69 BE
					15 00 00 00 00 00 02 6A 17
					15 00 00 00 00 00 02 6B 22
					15 00 00 00 00 00 02 6C 79
					15 00 00 00 00 00 02 6D E4
					15 00 00 00 00 00 02 6E 32
					15 00 00 00 00 00 02 6F 59
					15 00 00 00 00 00 02 70 D7
					15 00 00 00 00 00 02 71 43
					15 00 00 00 00 00 02 72 5F
					15 00 00 00 00 00 02 73 F1
					15 00 00 00 00 00 02 74 54
					15 00 00 00 00 00 02 75 8E
					15 00 00 00 00 00 02 76 34
					15 00 00 00 00 00 02 77 66
					15 00 00 00 00 00 02 78 E5
					15 00 00 00 00 00 02 79 A0
					15 00 00 00 00 00 02 7A 87
					15 00 00 00 00 00 02 7B 66
					15 00 00 00 00 00 02 7C 37
					15 00 00 00 00 00 02 7D A9
					15 00 00 00 00 00 02 7E 13
					15 00 00 00 00 00 02 7F F9
					15 00 00 00 00 00 02 80 BA
					15 00 00 00 00 00 02 81 EB
					15 00 00 00 00 00 02 82 E8
					15 00 00 00 00 00 02 83 DC
					15 00 00 00 00 00 02 84 F1
					15 00 00 00 00 00 02 85 04
					15 00 00 00 00 00 02 86 FF
					15 00 00 00 00 00 02 87 92
					15 00 00 00 00 00 02 88 DB
					15 00 00 00 00 00 02 89 FF
					15 00 00 00 00 00 02 8A FF
					15 00 00 00 00 00 02 8B 00
					15 00 00 00 00 00 02 8C 00
					15 00 00 00 00 00 02 8D 00
					15 00 00 00 00 00 02 8E 02
					15 00 00 00 00 00 02 8F 00
					15 00 00 00 00 00 02 90 08
					15 00 00 00 00 00 02 91 15
					15 00 00 00 00 00 02 92 00
					15 00 00 00 00 00 02 93 1D
					15 00 00 00 00 00 02 94 27
					15 00 00 00 00 00 02 95 00
					15 00 00 00 00 00 02 96 33
					15 00 00 00 00 00 02 97 3A
					15 00 00 00 00 00 02 98 00
					15 00 00 00 00 00 02 99 41
					15 00 00 00 00 00 02 9A 61
					15 00 00 00 00 00 02 9B 00
					15 00 00 00 00 00 02 9C 89
					15 00 00 00 00 00 02 9D A0
					15 00 00 00 00 00 02 9E 00
					15 00 00 00 00 00 02 9F B9
					15 00 00 00 00 00 02 A0 F1
					15 00 00 00 00 00 02 A2 10
					15 00 00 00 00 00 02 A3 31
					15 00 00 00 00 00 02 A4 7A
					15 00 00 00 00 00 02 A5 11
					15 00 00 00 00 00 02 A6 CB
					15 00 00 00 00 00 02 A7 25
					15 00 00 00 00 00 02 A9 22
					15 00 00 00 00 00 02 AA 88
					15 00 00 00 00 00 02 AB F5
					15 00 00 00 00 00 02 AC 32
					15 00 00 00 00 00 02 AD 6B
					15 00 00 00 00 00 02 AE EA
					15 00 00 00 00 00 02 AF 43
					15 00 00 00 00 00 02 B0 73
					15 00 00 00 00 00 02 B1 05
					15 00 00 00 00 00 02 B2 55
					15 00 00 00 00 00 02 B3 A2
					15 00 00 00 00 00 02 B4 48
					15 00 00 00 00 00 02 B5 66
					15 00 00 00 00 00 02 B6 F9
					15 00 00 00 00 00 02 B7 B4
					15 00 00 00 00 00 02 B8 87
					15 00 00 00 00 00 02 B9 79
					15 00 00 00 00 00 02 BA 48
					15 00 00 00 00 00 02 BB A9
					15 00 00 00 00 00 02 BC 23
					15 00 00 00 00 00 02 BD 07
					15 00 00 00 00 00 02 BE BB
					15 00 00 00 00 00 02 BF F7
					15 00 00 00 00 00 02 C0 F2
					15 00 00 00 00 00 02 C1 DC
					15 00 00 00 00 00 02 C2 F7
					15 00 00 00 00 00 02 C3 07
					15 00 00 00 00 00 02 C4 FF
					15 00 00 00 00 00 02 C5 94
					15 00 00 00 00 00 02 C6 DB
					15 00 00 00 00 00 02 C7 FF
					15 00 00 00 00 00 02 C8 FF
					15 01 00 00 00 00 02 FE 00
					15 00 00 00 00 00 02 FE 12
					15 00 00 00 00 00 02 00 00
					15 00 00 00 00 00 02 01 30
					15 00 00 00 00 00 02 02 00
					15 00 00 00 00 00 02 03 48
					15 00 00 00 00 00 02 04 60
					15 00 00 00 00 00 02 05 00
					15 00 00 00 00 00 02 06 88
					15 00 00 00 00 00 02 07 B8
					15 00 00 00 00 00 02 08 00
					15 00 00 00 00 00 02 09 F8
					15 00 00 00 00 00 02 0A 4E
					15 00 00 00 00 00 02 0B 10
					15 00 00 00 00 00 02 0C C4
					15 00 00 00 00 00 02 0D 1B
					15 00 00 00 00 00 02 0E 21
					15 00 00 00 00 00 02 0F 63
					15 00 00 00 00 00 02 10 D9
					15 00 00 00 00 00 02 11 22
					15 00 00 00 00 00 02 12 3A
					15 00 00 00 00 00 02 13 8E
					15 00 00 00 00 00 02 14 33
					15 00 00 00 00 00 02 15 D9
					15 00 00 00 00 00 02 16 5D
					15 00 00 00 00 00 02 17 43
					15 00 00 00 00 00 02 18 CE
					15 00 00 00 00 00 02 19 34
					15 00 00 00 00 00 02 1A 54
					15 00 00 00 00 00 02 1B 90
					15 00 00 00 00 00 02 1C E5
					15 00 00 00 00 00 02 1D 55
					15 00 00 00 00 00 02 1E 35
					15 00 00 00 00 00 02 1F 7F
					15 00 00 00 00 00 02 20 66
					15 00 00 00 00 00 02 21 C6
					15 00 00 00 00 00 02 22 08
					15 00 00 00 00 00 02 23 76
					15 00 00 00 00 00 02 24 48
					15 00 00 00 00 00 02 25 85
					15 00 00 00 00 00 02 26 77
					15 00 00 00 00 00 02 27 C0
					15 00 00 00 00 00 02 28 F8
					15 00 00 00 00 00 02 29 77
					15 00 00 00 00 00 02 2A 00
					15 00 00 00 00 00 02 2B 28
					15 00 00 00 00 00 02 2D 00
					15 00 00 00 00 00 02 2F 40
					15 00 00 00 00 00 02 30 60
					15 00 00 00 00 00 02 31 00
					15 00 00 00 00 00 02 32 80
					15 00 00 00 00 00 02 33 B0
					15 00 00 00 00 00 02 34 00
					15 00 00 00 00 00 02 35 F0
					15 00 00 00 00 00 02 36 46
					15 00 00 00 00 00 02 37 10
					15 00 00 00 00 00 02 38 BB
					15 00 00 00 00 00 02 39 12
					15 00 00 00 00 00 02 3A 21
					15 00 00 00 00 00 02 3B 59
					15 00 00 00 00 00 02 3D CF
					15 00 00 00 00 00 02 3F 22
					15 00 00 00 00 00 02 40 30
					15 00 00 00 00 00 02 41 84
					15 00 00 00 00 00 02 42 33
					15 00 00 00 00 00 02 43 D0
					15 00 00 00 00 00 02 44 54
					15 00 00 00 00 00 02 45 43
					15 00 00 00 00 00 02 46 C6
					15 00 00 00 00 00 02 47 2D
					15 00 00 00 00 00 02 48 54
					15 00 00 00 00 00 02 49 89
					15 00 00 00 00 00 02 4A DF
					15 00 00 00 00 00 02 4B 55
					15 00 00 00 00 00 02 4C 2F
					15 00 00 00 00 00 02 4D 7B
					15 00 00 00 00 00 02 4E 66
					15 00 00 00 00 00 02 4F C2
					15 00 00 00 00 00 02 50 05
					15 00 00 00 00 00 02 51 76
					15 00 00 00 00 00 02 52 46
					15 00 00 00 00 00 02 53 84
					15 00 00 00 00 00 02 54 77
					15 00 00 00 00 00 02 55 BF
					15 00 00 00 00 00 02 56 F8
					15 00 00 00 00 00 02 58 77
					15 00 00 00 00 00 02 59 00
					15 00 00 00 00 00 02 5A 28
					15 00 00 00 00 00 02 5B 00
					15 00 00 00 00 00 02 5C 40
					15 00 00 00 00 00 02 5D 58
					15 00 00 00 00 00 02 5E 00
					15 00 00 00 00 00 02 5F 80
					15 00 00 00 00 00 02 60 AC
					15 00 00 00 00 00 02 61 00
					15 00 00 00 00 00 02 62 EB
					15 00 00 00 00 00 02 63 3E
					15 00 00 00 00 00 02 64 10
					15 00 00 00 00 00 02 65 B2
					15 00 00 00 00 00 02 66 08
					15 00 00 00 00 00 02 67 21
					15 00 00 00 00 00 02 68 50
					15 00 00 00 00 00 02 69 C5
					15 00 00 00 00 00 02 6A 22
					15 00 00 00 00 00 02 6B 27
					15 00 00 00 00 00 02 6C 7B
					15 00 00 00 00 00 02 6D 33
					15 00 00 00 00 00 02 6E C6
					15 00 00 00 00 00 02 6F 4B
					15 00 00 00 00 00 02 70 43
					15 00 00 00 00 00 02 71 BE
					15 00 00 00 00 00 02 72 25
					15 00 00 00 00 00 02 73 54
					15 00 00 00 00 00 02 74 83
					15 00 00 00 00 00 02 75 D9
					15 00 00 00 00 00 02 76 55
					15 00 00 00 00 00 02 77 2A
					15 00 00 00 00 00 02 78 76
					15 00 00 00 00 00 02 79 66
					15 00 00 00 00 00 02 7A BE
					15 00 00 00 00 00 02 7B 02
					15 00 00 00 00 00 02 7C 76
					15 00 00 00 00 00 02 7D 44
					15 00 00 00 00 00 02 7E 82
					15 00 00 00 00 00 02 7F 77
					15 00 00 00 00 00 02 80 BE
					15 00 00 00 00 00 02 81 F8
					15 00 00 00 00 00 02 82 77
					15 01 00 00 00 00 02 FE 00
					15 00 00 00 00 00 02 FE 12
					15 00 00 00 00 00 02 84 00
					15 01 00 00 00 00 02 FE 00
					15 00 00 00 00 00 02 FE 12
					15 00 00 00 00 00 02 86 00
					15 00 00 00 00 00 02 87 00
					15 00 00 00 00 00 02 88 00
					15 00 00 00 00 00 02 83 10
					15 01 00 00 00 00 02 FE 00
					15 00 00 00 00 00 02 FE 40
					15 00 00 00 00 00 02 0D 18
					15 01 00 00 00 00 02 FE 00
					15 00 00 00 00 00 02 C2 08
					15 01 00 00 00 00 02 35 00
					05 01 00 00 78 00 01 11
					05 01 00 00 28 00 01 29
				];

				qcom,mdss-dsi-off-command = [
					05 01 00 00 20 00 01 28
					05 01 00 00 10 00 01 10
				];

				qcom,mdss-dsi-on-command-state = "dsi_lp_mode";
				qcom,mdss-dsi-off-command-state = "dsi_lp_mode";

				qcom,mode-control-dsi-state = "dsi_lp_mode";
			};

		};
	};
};
